# MCU_FSS0_OSPI0_ECC_AGGR register map
Vendor: Texas Instruments
Peripheral module from a debugger description file (folder J7VCL).
Registers are 32-bit, access not given, reset 0x0 unless marked. A register's access mark holds for its fields unless they carry their own. Offsets are as the file gives them; lines under a group give offsets from that group; [hi:lo] are bit positions; {n}, {i} and the like mark numbered series; 'fields as' and 'values as' point back to an identical list; <NAME> marks a mode.

## MCU_FSS0_OSPI0_ECC_AGGR
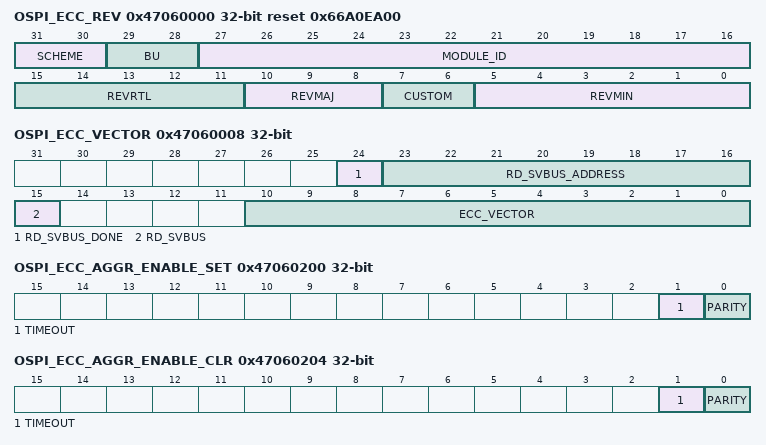
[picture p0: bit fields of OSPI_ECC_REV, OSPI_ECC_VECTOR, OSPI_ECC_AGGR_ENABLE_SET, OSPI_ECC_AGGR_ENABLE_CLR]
0x47060000 OSPI_ECC_REV ro reset 0x66A0EA00 — Revision parameters.
  [31:30] SCHEME
  [29:28] BU
  [27:16] MODULE_ID
  [15:11] REVRTL — RTL version
  [10:8] REVMAJ — Major version
  [7:6] CUSTOM — Custom version
  [5:0] REVMIN — Minor version
0x47060008 OSPI_ECC_VECTOR — ECC Vector Register.
  [24] RD_SVBUS_DONE — Status to indicate if read on serial VBUS is complete, write of any value will clear this bit. (access RW1C)
  [23:16] RD_SVBUS_ADDRESS rw — Read address
  [15] RD_SVBUS — Write 1 to trigger a read on the serial VBUS (access RW1S)
  [10:0] ECC_VECTOR rw — Value written to select the corresponding ECC RAM for control or status
0x4706000C OSPI_ECC_STAT ro reset 0x1 — Miscellaneous status register.
  [10:0] NUM_RAMS — Indicates the number of RAMs serviced by the ECC aggregator.
0x47060010 OSPI_RESERVED_SVBUS_Y rw — Reference other documents that contain the ECC RAM wrapper and EDC controller serial vbus register sets. Offset = 10h + (y * 4h); where y = 0h to 7h
  [31:0] DATA — Serial VBUS register data
0x4706003C OSPI_ECC_SEC_EOI_REG — EOI Register The EOI register is used to re-trigger the pulse interrupt signal to ensure that any nested interrupt events are serviced. The software interrupt handler must write to the EOI register at the end of the current interrupt processing routine, so that new events can re-trigger the pulse interrupt signal again. For level interrupt signals the EOI register is not functional and must not be used.
  [0] EOI_WR — EOI Register (access RW1S)
0x47060040 OSPI_ECC_SEC_STATUS_REG0 — Interrupt Status Register 0.
  [0] SRAM_PEND — Interrupt Pending Status for sram_pend (access RW1S)
0x47060080 OSPI_ECC_SEC_ENABLE_SET_REG0 — Interrupt Enable Set Register 0.
  [0] SRAM_ENABLE_SET — Interrupt Enable Set Register for sram_pend (access RW1S)
0x470600C0 OSPI_ECC_SEC_ENABLE_CLR_REG0 — Interrupt Enable Clear Register 0.
  [0] SRAM_ENABLE_CLR — Interrupt Enable Clear Register for sram_pend (access RW1C)
0x4706013C OSPI_ECC_DED_EOI_REG — EOI Register. The EOI register is used to re-trigger the pulse interrupt signal to ensure that any nested interrupt events are serviced. The software interrupt handler must write to the EOI register at the end of the current interrupt processing routine, so that new events can re-trigger the pulse interrupt signal again. For level interrupt signals the EOI register is not functional and must not be used.
  [0] EOI_WR — EOI Register (access RW1S)
0x47060140 OSPI_ECC_DED_STATUS_REG0 — Interrupt Status Register 0.
  [0] SRAM_PEND — Interrupt Pending Status for sram_pend. (access RW1S)
0x47060180 OSPI_ECC_DED_ENABLE_SET_REG0 — Interrupt Enable Set Register 0.
  [0] SRAM_ENABLE_SET — Interrupt Enable Set Register for sram_pend. (access RW1S)
0x470601C0 OSPI_ECC_DED_ENABLE_CLR_REG0 — Interrupt Enable Clear Register 0.
  [0] SRAM_ENABLE_CLR — Interrupt Enable Clear Register for sram_pend. (access RW1C)
0x47060200 OSPI_ECC_AGGR_ENABLE_SET — AGGR interrupt enable set register.
  [1] TIMEOUT — Interrupt enable set for svbus timeout errors. (access RW1S)
  [0] PARITY — Interrupt enable set for parity errors. (access RW1S)
0x47060204 OSPI_ECC_AGGR_ENABLE_CLR — AGGR interrupt enable clear register.
  [1] TIMEOUT — Interrupt enable clear for svbus timeout errors. (access RW1C)
  [0] PARITY — Interrupt enable clear for parity errors. (access RW1C)
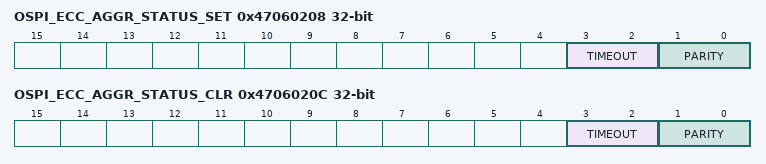
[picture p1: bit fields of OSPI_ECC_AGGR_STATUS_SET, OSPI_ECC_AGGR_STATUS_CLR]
0x47060208 OSPI_ECC_AGGR_STATUS_SET — AGGR interrupt status set register.
  [3:2] TIMEOUT — Interrupt status set for svbus timeout errors. (access RWincr)
  [1:0] PARITY — Interrupt status set for parity errors. (access RWincr)
0x4706020C OSPI_ECC_AGGR_STATUS_CLR — AGGR interrupt status clear register.
  [3:2] TIMEOUT — Interrupt status clear for svbus timeout errors. (access RWdecr)
  [1:0] PARITY — Interrupt status clear for parity errors. (access RWdecr)
